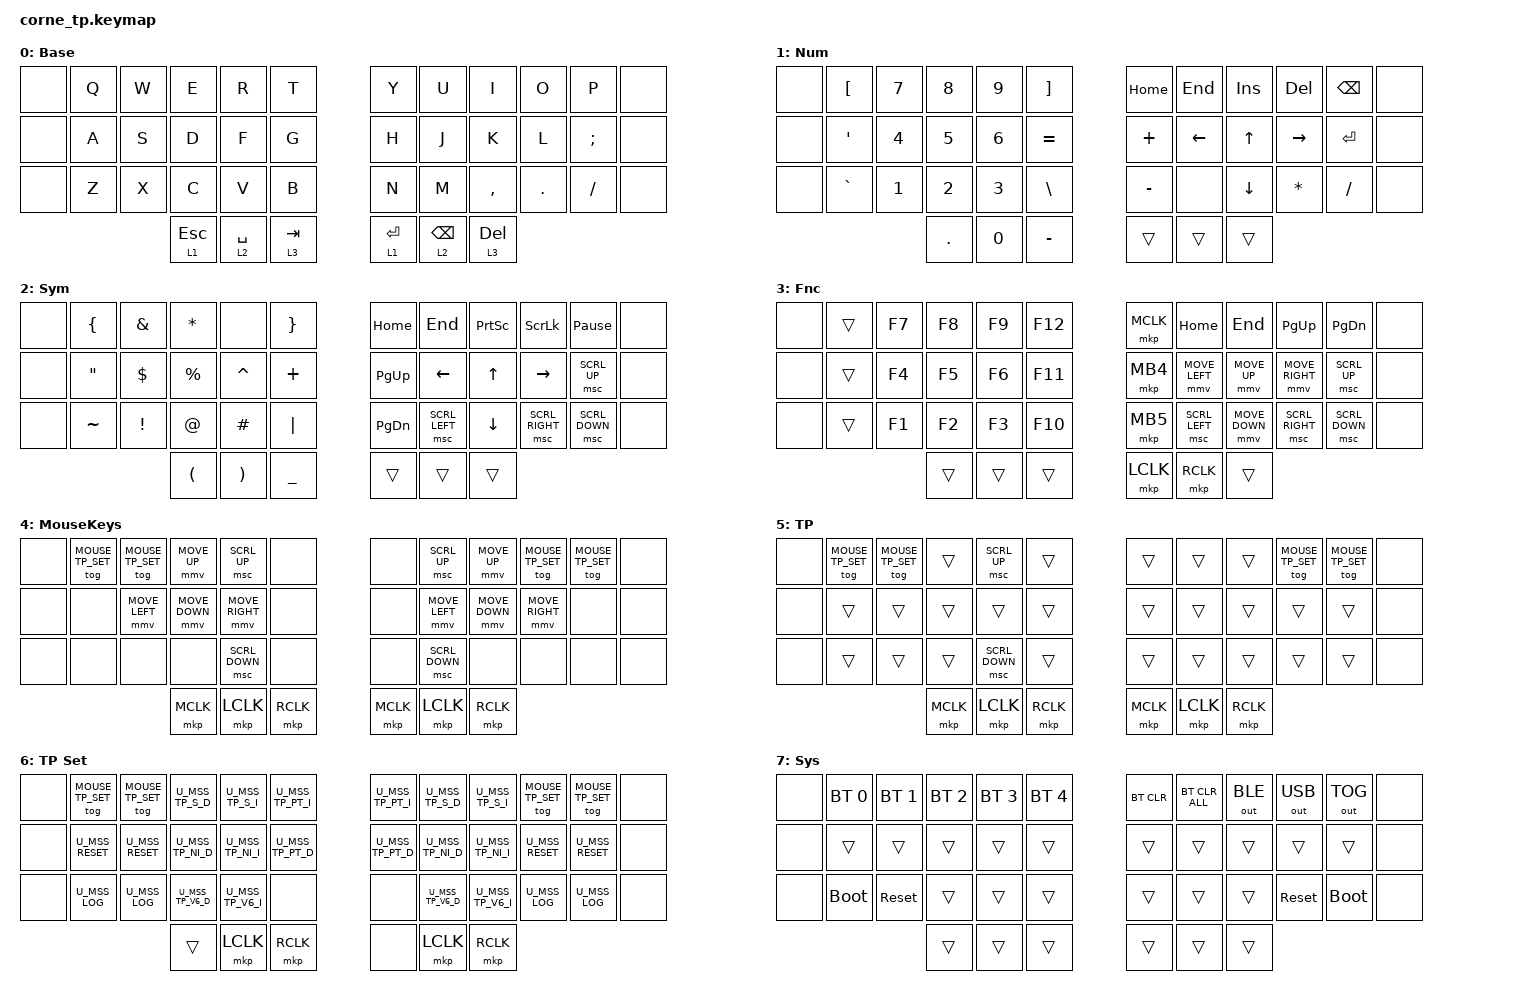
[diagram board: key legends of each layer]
/*
 * Copyright (c) 2020 The ZMK Contributors
 *
 * SPDX-License-Identifier: MIT
 */

#include <behaviors.dtsi>
#include <dt-bindings/zmk/keys.h>
#include <dt-bindings/zmk/bt.h>
#include <dt-bindings/zmk/outputs.h>

#define BASE 0
#define NUM 1
#define SYM 2
#define FNC 3
#define MOUSE_KEYS 4
#define MOUSE_TP 5
#define MOUSE_TP_SET 6
#define SYS 7

/*
 * Defines to enable/disable features
 *
 * These defines allow us to conditionally enable and disable parts of the keymap config.
 *
 * For example, if we decide to build the firmware without the mouse features, we can
 * disable all the config options that rely on those forks and modules without having
 * to edit the entire keymap file manually every time.
 */

#define HAS_MOUSE_KEYS
#define HAS_MOUSE_TP

#ifdef HAS_MOUSE_KEYS
  #include <dt-bindings/zmk/mouse.h>
  #include <behaviors/mouse_keys.dtsi>
#endif  // HAS_MOUSE_KEYS

#ifdef HAS_MOUSE_TP
  // We store the trackpoint settings in a separate file
  // to make organization a little easier.
  #include "include/mouse_tp.dtsi"
#endif  // HAS_MOUSE_TP



// Adjust layer keys based on enabled features.
//
// This prevents build errors when we build the firmware
// without the mouse keys PR or the TP module.
#ifdef HAS_MOUSE_KEYS
  #define U_THUMB_INNER &mo MOUSE_KEYS
#else
  #define U_THUMB_INNER &none
#endif  // HAS_MOUSE_KEYS

#ifdef HAS_MOUSE_TP
  #define U_TOG_TP_SET &tog MOUSE_TP_SET
#else
  #define U_TOG_TP_SET &none
#endif  // HAS_MOUSE_TP

&lt {
    flavor = "tap-preferred";
    quick-tap-ms = <180>;
};

&mt {
    quick-tap-ms = <150>;
    flavor = "tap-preferred";
};

/ {
    combos {
        compatible = "zmk,combos";

        combo_esc {
            bindings = <&kp ESC>;
            key-positions = <1 2>;
            timeout-ms = <50>;
            require-prior-idle-ms = <100>;
            layers = <0 1 2 3>;
            slow-release;
        };

        combo_lshft {
            bindings = <&kp LSHIFT>;
            key-positions = <15 16>;
            timeout-ms = <50>;
            require-prior-idle-ms = <100>;
            layers = <0 1 2 3>;
            slow-release;
        };

        combo_lctrl {
            bindings = <&kp LCTRL>;
            key-positions = <14 15>;
            timeout-ms = <50>;
            require-prior-idle-ms = <100>;
            layers = <0 1 2 3>;
            slow-release;
        };

        combo_lalt {
            bindings = <&kp LALT>;
            key-positions = <13 14>;
            timeout-ms = <50>;
            require-prior-idle-ms = <100>;
            layers = <0 1 2 3>;
            slow-release;
        };

        combo_lwin {
            bindings = <&kp LWIN>;
            key-positions = <16 17>;
            timeout-ms = <50>;
            require-prior-idle-ms = <100>;
            layers = <0 1 2 3>;
            slow-release;
        };

        combo_rshft {
            bindings = <&kp LSHIFT>;
            key-positions = <19 20>;
            timeout-ms = <50>;
            require-prior-idle-ms = <100>;
            layers = <0 1 2 3>;
            slow-release;
        };

        combo_rctrl {
            bindings = <&kp LCTRL>;
            key-positions = <20 21>;
            timeout-ms = <50>;
            require-prior-idle-ms = <100>;
            layers = <0 1 2 3>;
            slow-release;
        };

        combo_ralt {
            bindings = <&kp LALT>;
            key-positions = <21 22>;
            timeout-ms = <50>;
            require-prior-idle-ms = <100>;
            layers = <0 1 2 3>;
            slow-release;
        };

        combo_rwin {
            bindings = <&kp LWIN>;
            key-positions = <18 19>;
            timeout-ms = <50>;
            require-prior-idle-ms = <100>;
            layers = <0 1 2 3>;
            slow-release;
        };

        combo_lshft_lctrl {
            bindings = <&kp LC(LSHIFT)>;
            key-positions = <14 15 16>;
            timeout-ms = <50>;
            require-prior-idle-ms = <100>;
            layers = <0 1 2 3>;
            slow-release;
        };

        combo_lshft_lalt {
            bindings = <&kp LA(LSHIFT)>;
            key-positions = <13 15 16>;
            timeout-ms = <50>;
            require-prior-idle-ms = <100>;
            layers = <0 1 2 3>;
            slow-release;
        };

        combo_lctrl_lalt {
            bindings = <&kp LA(LCTRL)>;
            key-positions = <13 14 15>;
            timeout-ms = <50>;
            require-prior-idle-ms = <100>;
            layers = <0 1 2 3>;
            slow-release;
        };

        combo_lctrl_lwin {
            bindings = <&kp LG(LCTRL)>;
            key-positions = <13 14 15 16>;
            timeout-ms = <50>;
            require-prior-idle-ms = <100>;
            layers = <0 1 2 3>;
            slow-release;
        };

        combo_rshft_rctrl {
            bindings = <&kp LC(LSHIFT)>;
            key-positions = <19 20 21>;
            timeout-ms = <50>;
            require-prior-idle-ms = <100>;
            layers = <0 1 2 3>;
            slow-release;
        };

        combo_rshft_ralt {
            bindings = <&kp LA(LSHIFT)>;
            key-positions = <19 20 22>;
            timeout-ms = <50>;
            require-prior-idle-ms = <100>;
            layers = <0 1 2 3>;
            slow-release;
        };

        combo_rctrl_ralt {
            bindings = <&kp LA(LCTRL)>;
            key-positions = <20 21 22>;
            timeout-ms = <50>;
            require-prior-idle-ms = <100>;
            layers = <0 1 2 3>;
            slow-release;
        };

        combo_rctrl_rwin {
            bindings = <&kp LG(LCTRL)>;
            key-positions = <19 20 21 22>;
            timeout-ms = <50>;
            require-prior-idle-ms = <100>;
            layers = <0 1 2 3>;
            slow-release;
        };

        combo_lang {
            bindings = <&kp RALT>;
            key-positions = <7 19>;
            timeout-ms = <50>;
            require-prior-idle-ms = <100>;
            layers = <0 1 2 3>;
            slow-release;
        };

        combo_hanja {
            bindings = <&kp RCTRL>;
            key-positions = <8 20>;
            timeout-ms = <50>;
            require-prior-idle-ms = <100>;
            layers = <0 1 2 3>;
            slow-release;
        };

        combo_undo {
            bindings = <&kp LC(Z)>;
            key-positions = <25 26>;
            timeout-ms = <50>;
            require-prior-idle-ms = <100>;
            layers = <0 1 2 3>;
            slow-release;
        };

        combo_copy {
            bindings = <&kp LC(C)>;
            key-positions = <26 27>;
            timeout-ms = <50>;
            require-prior-idle-ms = <100>;
            layers = <0 1 2 3>;
            slow-release;
        };

        combo_cut {
            bindings = <&kp LC(X)>;
            key-positions = <26 28>;
            timeout-ms = <50>;
            require-prior-idle-ms = <100>;
            layers = <0 1 2 3>;
            slow-release;
        };

        combo_paste {
            bindings = <&kp LC(V)>;
            key-positions = <27 28>;
            timeout-ms = <50>;
            require-prior-idle-ms = <100>;
            layers = <0 1 2 3>;
            slow-release;
        };

        combo_redo {
            bindings = <&kp LC(Y)>;
            key-positions = <28 29>;
            timeout-ms = <50>;
            require-prior-idle-ms = <100>;
            layers = <0 1 2 3>;
            slow-release;
        };

        combo_plus {
            bindings = <&kp PLUS>;
            key-positions = <5 17>;
            timeout-ms = <50>;
            require-prior-idle-ms = <100>;
            layers = <1>;
            slow-release;
        };

        combo_minus {
            bindings = <&kp MINUS>;
            key-positions = <4 16>;
            timeout-ms = <50>;
            require-prior-idle-ms = <100>;
            layers = <1>;
            slow-release;
        };

        combo_multiply {
            bindings = <&kp ASTRK>;
            key-positions = <3 15>;
            timeout-ms = <50>;
            require-prior-idle-ms = <100>;
            layers = <1>;
            slow-release;
        };

        combo_divide {
            bindings = <&kp SLASH>;
            key-positions = <2 14>;
            timeout-ms = <50>;
            require-prior-idle-ms = <100>;
            layers = <1>;
            slow-release;
        };

        combo_comma {
            bindings = <&kp COMMA>;
            key-positions = <16 28>;
            timeout-ms = <50>;
            require-prior-idle-ms = <100>;
            layers = <1>;
            slow-release;
        };

        combo_enter {
            bindings = <&kp ENTER>;
            key-positions = <17 29>;
            timeout-ms = <50>;
            require-prior-idle-ms = <100>;
            layers = <1>;
            slow-release;
        };

        combo_prev {
            bindings = <&mkp MB4>;
            key-positions = <19 31>;
            timeout-ms = <50>;
            require-prior-idle-ms = <100>;
            layers = <0 1 2 3>;
            slow-release;
        };

        combo_next {
            bindings = <&mkp MB5>;
            key-positions = <20 32>;
            timeout-ms = <50>;
            require-prior-idle-ms = <100>;
            layers = <0 1 2 3>;
            slow-release;
        };

        combl_lclk {
            bindings = <&mkp LCLK>;
            key-positions = <31 32>;
            timeout-ms = <50>;
            require-prior-idle-ms = <100>;
            layers = <0 1 2 3>;
            slow-release;
        };

        combo_rclk {
            bindings = <&mkp RCLK>;
            key-positions = <32 33>;
            timeout-ms = <50>;
            require-prior-idle-ms = <100>;
            layers = <0 1 2 3>;
            slow-release;
        };

        combo_mclk {
            bindings = <&mkp MCLK>;
            key-positions = <31 33>;
            timeout-ms = <50>;
            require-prior-idle-ms = <100>;
            layers = <0 1 2 3>;
            slow-release;
        };
    };

// Disable line-wrap in your editor to see a "visualization" of the key layouts

  keymap {
    compatible = "zmk,keymap";

    Base_layer {
      display-name = "Base";
      bindings = <
// ╭────────────────┬────────────────┬────────────────┬────────────────┬────────────────┬────────────────╮ ╭────────────────┬────────────────┬────────────────┬────────────────┬────────────────┬────────────────╮
    &none            &kp Q            &kp W            &kp E            &kp R            &kp T              &kp Y            &kp U            &kp I            &kp O            &kp P            &none
// ├────────────────┼────────────────┼────────────────┼────────────────┼────────────────┼────────────────┤ ├────────────────┼────────────────┼────────────────┼────────────────┼────────────────┼────────────────┤
    &none            &kp A            &kp S            &kp D            &kp F            &kp G              &kp H            &kp J            &kp K            &kp L            &kp SEMI         &none
// ├────────────────┼────────────────┼────────────────┼────────────────┼────────────────┼────────────────┤ ├────────────────┼────────────────┼────────────────┼────────────────┼────────────────┼────────────────┤
    &none            &kp Z            &kp X            &kp C            &kp V            &kp B              &kp N            &kp M            &kp COMMA        &kp DOT          &kp SLASH        &none
// ╰────────────────┴────────────────┴────────────────┴────────────────┼────────────────┼────────────────┤ ├────────────────┼────────────────┼────────────────┼────────────────┴────────────────┴────────────────╯
                                                       &lt 1 ESC        &lt 2 SPACE      &lt 3 TAB          &lt 1 ENTER      &lt 2 BSPC       &lt 3 DEL
//                                                    ╰────────────────┴────────────────┴────────────────╯ ╰────────────────┴────────────────┴────────────────╯

      >;
    };


    Num_layer {
      display-name = "Num";
      bindings = <
// ╭────────────────┬────────────────┬────────────────┬────────────────┬────────────────┬────────────────╮ ╭────────────────┬────────────────┬────────────────┬────────────────┬────────────────┬────────────────╮
    &none            &kp LBKT         &kp N7           &kp N8           &kp N9           &kp RBKT           &kp HOME         &kp END          &kp INS          &kp DEL          &kp BSPC         &none
// ├────────────────┼────────────────┼────────────────┼────────────────┼────────────────┼────────────────┤ ├────────────────┼────────────────┼────────────────┼────────────────┼────────────────┼────────────────┤
    &none            &kp SQT          &kp N4           &kp N5           &kp N6           &kp EQUAL          &kp PLUS         &kp LEFT         &kp UP           &kp RIGHT        &kp ENTER        &none
// ├────────────────┼────────────────┼────────────────┼────────────────┼────────────────┼────────────────┤ ├────────────────┼────────────────┼────────────────┼────────────────┼────────────────┼────────────────┤
    &none            &kp GRAVE        &kp N1           &kp N2           &kp N3           &kp BSLH           &kp MINUS        &none            &kp DOWN         &kp ASTRK        &kp SLASH        &none
// ╰────────────────┴────────────────┴────────────────┴────────────────┼────────────────┼────────────────┤ ├────────────────┼────────────────┼────────────────┼────────────────┴────────────────┴────────────────╯
                                                       &kp DOT          &kp N0           &kp MINUS          &trans           &trans           &trans
//                                                    ╰────────────────┴────────────────┴────────────────╯ ╰────────────────┴────────────────┴────────────────╯
      >;
    };

    Sym_layer {
      display-name = "Sym";
      bindings = <
// ╭────────────────┬────────────────┬────────────────┬────────────────┬────────────────┬────────────────╮ ╭────────────────┬────────────────┬────────────────┬────────────────┬────────────────┬────────────────╮
    &none            &kp LBRC         &kp AMPS         &kp ASTRK        &none            &kp RBRC           &kp HOME         &kp END          &kp PRINTSCREEN  &kp SCROLLLOCK   &kp PAUSE_BREAK  &none
// ├────────────────┼────────────────┼────────────────┼────────────────┼────────────────┼────────────────┤ ├────────────────┼────────────────┼────────────────┼────────────────┼────────────────┼────────────────┤
    &none            &kp DQT          &kp DLLR         &kp PRCNT        &kp CARET        &kp PLUS           &kp PG_UP        &kp LEFT         &kp UP           &kp RIGHT        &msc SCRL_UP     &none
// ├────────────────┼────────────────┼────────────────┼────────────────┼────────────────┼────────────────┤ ├────────────────┼────────────────┼────────────────┼────────────────┼────────────────┼────────────────┤
    &none            &kp TILDE        &kp EXCL         &kp AT           &kp HASH         &kp PIPE           &kp PG_DN        &msc SCRL_LEFT   &kp DOWN         &msc SCRL_RIGHT  &msc SCRL_DOWN   &none
// ╰────────────────┴────────────────┴────────────────┴────────────────┼────────────────┼────────────────┤ ├────────────────┼────────────────┼────────────────┼────────────────┴────────────────┴────────────────╯
                                                       &kp LPAR         &kp RPAR         &kp UNDER          &trans           &trans           &trans
//                                                    ╰────────────────┴────────────────┴────────────────╯ ╰────────────────┴────────────────┴────────────────╯
      >;
    };

    Fnc_layer {
      display-name = "Fnc";
      bindings = <
// ╭────────────────┬────────────────┬────────────────┬────────────────┬────────────────┬────────────────╮ ╭────────────────┬────────────────┬────────────────┬────────────────┬────────────────┬────────────────╮
    &none            &trans           &kp F7           &kp F8           &kp F9           &kp F12            &mkp MCLK        &kp HOME         &kp END          &kp PG_UP        &kp PG_DN        &none
// ├────────────────┼────────────────┼────────────────┼────────────────┼────────────────┼────────────────┤ ├────────────────┼────────────────┼────────────────┼────────────────┼────────────────┼────────────────┤
    &none            &trans           &kp F4           &kp F5           &kp F6           &kp F11            &mkp MB4         &mmv MOVE_LEFT   &mmv MOVE_UP     &mmv MOVE_RIGHT  &msc SCRL_UP     &none
// ├────────────────┼────────────────┼────────────────┼────────────────┼────────────────┼────────────────┤ ├────────────────┼────────────────┼────────────────┼────────────────┼────────────────┼────────────────┤
    &none            &trans           &kp F1           &kp F2           &kp F3           &kp F10            &mkp MB5         &msc SCRL_LEFT   &mmv MOVE_DOWN   &msc SCRL_RIGHT  &msc SCRL_DOWN   &none
// ╰────────────────┴────────────────┴────────────────┴────────────────┼────────────────┼────────────────┤ ├────────────────┼────────────────┼────────────────┼────────────────┴────────────────┴────────────────╯
                                                       &trans           &trans           &trans             &mkp LCLK        &mkp RCLK        &trans
//                                                    ╰────────────────┴────────────────┴────────────────╯ ╰────────────────┴────────────────┴────────────────╯
      >;
    };


#ifdef HAS_MOUSE_KEYS

    MouseKeys_layer {
      display-name = "MouseKeys";
      bindings = <
// ╭────────────────┬────────────────┬────────────────┬────────────────┬────────────────┬────────────────╮ ╭────────────────┬────────────────┬────────────────┬────────────────┬────────────────┬────────────────╮
    &none            U_TOG_TP_SET     U_TOG_TP_SET     &mmv MOVE_UP     &msc SCRL_UP     &none              &none            &msc SCRL_UP     &mmv MOVE_UP     U_TOG_TP_SET     U_TOG_TP_SET     &none
// ├────────────────┼────────────────┼────────────────┼────────────────┼────────────────┼────────────────┤ ├────────────────┼────────────────┼────────────────┼────────────────┼────────────────┼────────────────┤
    &none            &none            &mmv MOVE_LEFT   &mmv MOVE_DOWN   &mmv MOVE_RIGHT  &none              &none            &mmv MOVE_LEFT   &mmv MOVE_DOWN   &mmv MOVE_RIGHT  &none            &none
// ├────────────────┼────────────────┼────────────────┼────────────────┼────────────────┼────────────────┤ ├────────────────┼────────────────┼────────────────┼────────────────┼────────────────┼────────────────┤
    &none            &none            &none            &none            &msc SCRL_DOWN   &none              &none            &msc SCRL_DOWN   &none            &none            &none            &none
// ╰────────────────┴────────────────┴────────────────┴────────────────┼────────────────┼────────────────┤ ├────────────────┼────────────────┼────────────────┼────────────────┴────────────────┴────────────────╯
                                                       &mkp MCLK        &mkp LCLK        &mkp RCLK          &mkp MCLK        &mkp LCLK        &mkp RCLK
//                                                    ╰────────────────┴────────────────┴────────────────╯ ╰────────────────┴────────────────┴────────────────╯
      >;
    };

#endif

#ifdef HAS_MOUSE_TP

    // Automatically activated when the mouse or trackpoint moves.
    // Configured in `include/mouse_tp.dtsi`.
    MouseTP_layer {
      display-name = "TP";
      bindings = <
// ╭────────────────┬────────────────┬────────────────┬────────────────┬────────────────┬────────────────╮ ╭────────────────┬────────────────┬────────────────┬────────────────┬────────────────┬────────────────╮
    &none            U_TOG_TP_SET     U_TOG_TP_SET     &trans           &msc SCRL_UP     &trans             &trans           &trans           &trans           U_TOG_TP_SET     U_TOG_TP_SET     &none
// ├────────────────┼────────────────┼────────────────┼────────────────┼────────────────┼────────────────┤ ├────────────────┼────────────────┼────────────────┼────────────────┼────────────────┼────────────────┤
    &none            &trans           &trans           &trans           &trans           &trans             &trans           &trans           &trans           &trans           &trans           &none
// ├────────────────┼────────────────┼────────────────┼────────────────┼────────────────┼────────────────┤ ├────────────────┼────────────────┼────────────────┼────────────────┼────────────────┼────────────────┤
    &none            &trans           &trans           &trans           &msc SCRL_DOWN   &trans             &trans           &trans           &trans           &trans           &trans           &none
// ╰────────────────┴────────────────┴────────────────┴────────────────┼────────────────┼────────────────┤ ├────────────────┼────────────────┼────────────────┼────────────────┴────────────────┴────────────────╯
                                                       &mkp MCLK        &mkp LCLK        &mkp RCLK          &mkp MCLK        &mkp LCLK        &mkp RCLK
//                                                    ╰────────────────┴────────────────┴────────────────╯ ╰────────────────┴────────────────┴────────────────╯
      >;
    };

    // You can find the defines for the actual key press behaviors in `include/mouse_tp.dtsi`.
    MouseSettings_layer {
      display-name = "TP Set";
      bindings = <
// ╭────────────────┬────────────────┬────────────────┬────────────────┬────────────────┬────────────────╮ ╭────────────────┬────────────────┬────────────────┬────────────────┬────────────────┬────────────────╮
    &none            U_TOG_TP_SET     U_TOG_TP_SET     U_MSS_TP_S_D     U_MSS_TP_S_I     U_MSS_TP_PT_I      U_MSS_TP_PT_I    U_MSS_TP_S_D     U_MSS_TP_S_I     U_TOG_TP_SET     U_TOG_TP_SET     &none
// ├────────────────┼────────────────┼────────────────┼────────────────┼────────────────┼────────────────┤ ├────────────────┼────────────────┼────────────────┼────────────────┼────────────────┼────────────────┤
    &none            U_MSS_RESET      U_MSS_RESET      U_MSS_TP_NI_D    U_MSS_TP_NI_I    U_MSS_TP_PT_D      U_MSS_TP_PT_D    U_MSS_TP_NI_D    U_MSS_TP_NI_I    U_MSS_RESET      U_MSS_RESET      &none
// ├────────────────┼────────────────┼────────────────┼────────────────┼────────────────┼────────────────┤ ├────────────────┼────────────────┼────────────────┼────────────────┼────────────────┼────────────────┤
    &none            U_MSS_LOG        U_MSS_LOG        U_MSS_TP_V6_D    U_MSS_TP_V6_I    &none              &none            U_MSS_TP_V6_D    U_MSS_TP_V6_I    U_MSS_LOG        U_MSS_LOG        &none
// ╰────────────────┴────────────────┴────────────────┴────────────────┼────────────────┼────────────────┤ ├────────────────┼────────────────┼────────────────┼────────────────┴────────────────┴────────────────╯
                                                       &trans           &mkp LCLK        &mkp RCLK          &none            &mkp LCLK        &mkp RCLK
//                                                    ╰────────────────┴────────────────┴────────────────╯ ╰────────────────┴────────────────┴────────────────╯
      >;
    };

#endif

    Sys_layer {
      display-name = "Sys";
      bindings = <
// ╭────────────────┬────────────────┬────────────────┬────────────────┬────────────────┬────────────────╮ ╭────────────────┬────────────────┬────────────────┬────────────────┬────────────────┬────────────────╮
    &none            &bt BT_SEL 0     &bt BT_SEL 1     &bt BT_SEL 2     &bt BT_SEL 3     &bt BT_SEL 4       &bt BT_CLR       &bt BT_CLR_ALL   &out OUT_BLE     &out OUT_USB     &out OUT_TOG     &none
// ├────────────────┼────────────────┼────────────────┼────────────────┼────────────────┼────────────────┤ ├────────────────┼────────────────┼────────────────┼────────────────┼────────────────┼────────────────┤
    &none            &trans           &trans           &trans           &trans           &trans             &trans           &trans           &trans           &trans           &trans           &none
// ├────────────────┼────────────────┼────────────────┼────────────────┼────────────────┼────────────────┤ ├────────────────┼────────────────┼────────────────┼────────────────┼────────────────┼────────────────┤
    &none            &bootloader      &sys_reset       &trans           &trans           &trans             &trans           &trans           &trans           &sys_reset       &bootloader      &none
// ╰────────────────┴────────────────┴────────────────┴────────────────┼────────────────┼────────────────┤ ├────────────────┼────────────────┼────────────────┼────────────────┴────────────────┴────────────────╯
                                                       &trans           &trans           &trans             &trans           &trans           &trans
//                                                    ╰────────────────┴────────────────┴────────────────╯ ╰────────────────┴────────────────┴────────────────╯
      >;
    };
  };

    conditional_layers {
        compatible = "zmk,conditional-layers";

        Sys_layer {
            if-layers = <1 3>;
            then-layer = <7>;
        };
    };

};
